# STM32F107 register map
File version: 1.1
CPU: CM3 r1p1, little endian, no MPU, no FPU, 4 interrupt priority bits
Registers are 32-bit, read-write, reset 0x0 unless marked. A register's access mark holds for its fields unless they carry their own. Offsets are from the block's base; [hi:lo] are bit positions.

## Ethernet_MMC — Ethernet: MAC management counters
Base 0x40028100
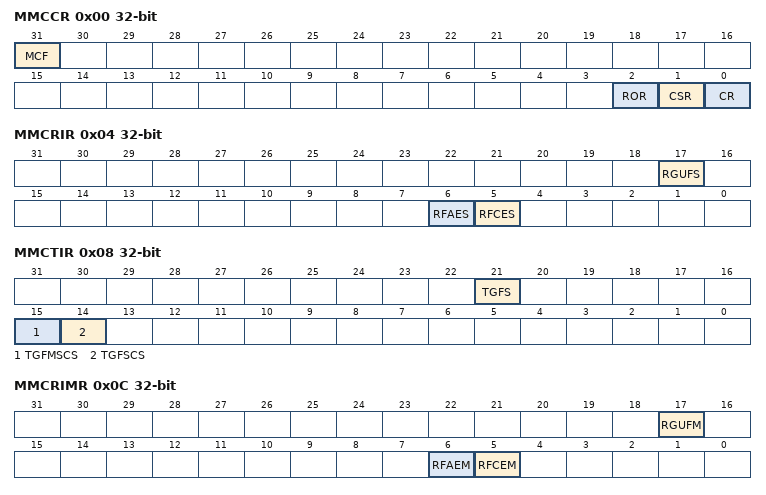
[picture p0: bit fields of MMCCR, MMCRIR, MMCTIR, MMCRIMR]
0x00 MMCCR — Ethernet MMC control register (ETH_MMCCR)
  [31] MCF — MMC counter freeze
    0=Unfrozen (All MMC counters update normally); 1=Frozen (All MMC counters frozen to their current value)
  [2] ROR — Reset on read
    0=Disabled (MMC counters do not reset on read); 1=Enabled (MMC counters reset to zero after read)
  [1] CSR — Counter stop rollover
    0=Disabled (Counters roll over to zero after reaching the maximum value); 1=Enabled (Counters do not roll over to zero after reaching the maximum value)
  [0] CR — Counter reset
    1=Reset all counters. Cleared automatically
0x04 MMCRIR — Ethernet MMC receive interrupt register (ETH_MMCRIR)
  [17] RGUFS — Received good Unicast frames status
  [6] RFAES — Received frames alignment error status
  [5] RFCES — Received frames CRC error status
0x08 MMCTIR — Ethernet MMC transmit interrupt register (ETH_MMCTIR)
  [21] TGFS — Transmitted good frames status
  [15] TGFMSCS — Transmitted good frames more than single collision status
  [14] TGFSCS — Transmitted good frames single collision status
0x0C MMCRIMR — Ethernet MMC receive interrupt mask register (ETH_MMCRIMR)
  [17] RGUFM — Received good Unicast frames mask
    0=Unmasked (Received-good-unicast counter half-full interrupt enabled); 1=Masked (Received-good-unicast counter half-full interrupt disabled)
  [6] RFAEM — Received frames alignment error mask
    0=Unmasked (Received-alignment-error counter half-full interrupt enabled); 1=Masked (Received-alignment-error counter half-full interrupt disabled)
  [5] RFCEM — Received frame CRC error mask
    0=Unmasked (Received-crc-error counter half-full interrupt enabled); 1=Masked (Received-crc-error counter half-full interrupt disabled)
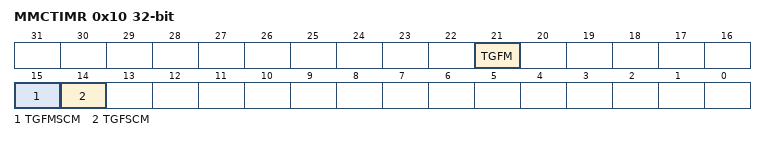
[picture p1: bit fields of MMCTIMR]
0x10 MMCTIMR — Ethernet MMC transmit interrupt mask register (ETH_MMCTIMR)
  [21] TGFM — Transmitted good frames mask
    0=Unmasked (Transmitted-good counter half-full interrupt enabled); 1=Masked (Transmitted-good counter half-full interrupt disabled)
  [15] TGFMSCM — Transmitted good frames more than single collision mask
    0=Unmasked (Transmitted-good-multiple-collision half-full interrupt enabled); 1=Masked (Transmitted-good-multiple-collision half-full interrupt disabled)
  [14] TGFSCM — Transmitted good frames single collision mask
    0=Unmasked (Transmitted-good-single-collision half-full interrupt enabled); 1=Masked (Transmitted-good-single-collision half-full interrupt disabled)
0x4C MMCTGFSCCR ro — Ethernet MMC transmitted good frames after a single collision counter
  [31:0] TGFSCC — Transmitted good frames single collision counter
0x50 MMCTGFMSCCR ro — Ethernet MMC transmitted good frames after more than a single collision
  [31:0] TGFMSCC — Transmitted good frames after more than a single collision counter
0x68 MMCTGFCR ro — Ethernet MMC transmitted good frames counter register
  [31:0] TGFC — Transmitted good frames counter
0x94 MMCRFCECR ro — Ethernet MMC received frames with CRC error counter register
  [31:0] RFCFC — Received frames with CRC error counter
0x98 MMCRFAECR ro — Ethernet MMC received frames with alignment error counter register
  [31:0] RFAEC — Received frames with alignment error counter
0xC4 MMCRGUFCR ro — MMC received good unicast frames counter register
  [31:0] RGUFC — Received good unicast frames counter

## Ethernet_PTP — Ethernet: Precision time protocol
Base 0x40028700
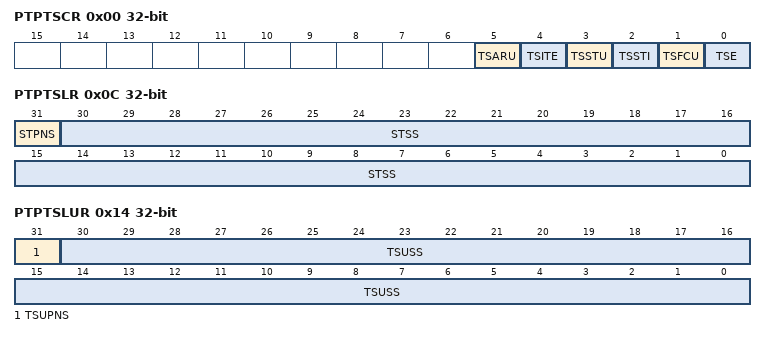
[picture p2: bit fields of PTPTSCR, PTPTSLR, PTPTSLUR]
0x00 PTPTSCR — Ethernet PTP time stamp control register (ETH_PTPTSCR)
  [5] TSARU — Time stamp addend register update
  [4] TSITE — Time stamp interrupt trigger enable
  [3] TSSTU — Time stamp system time update
  [2] TSSTI — Time stamp system time initialize
  [1] TSFCU — Time stamp fine or coarse update
  [0] TSE — Time stamp enable
0x04 PTPSSIR — Ethernet PTP subsecond increment register
  [7:0] STSSI — System time subsecond increment
0x08 PTPTSHR ro — Ethernet PTP time stamp high register
  [31:0] STS — System time second
0x0C PTPTSLR ro — Ethernet PTP time stamp low register (ETH_PTPTSLR)
  [31] STPNS — System time positive or negative sign
  [30:0] STSS — System time subseconds
0x10 PTPTSHUR — Ethernet PTP time stamp high update register
  [31:0] TSUS — Time stamp update second
0x14 PTPTSLUR — Ethernet PTP time stamp low update register (ETH_PTPTSLUR)
  [31] TSUPNS — Time stamp update positive or negative sign
  [30:0] TSUSS — Time stamp update subseconds
0x18 PTPTSAR — Ethernet PTP time stamp addend register
  [31:0] TSA — Time stamp addend
0x1C PTPTTHR — Ethernet PTP target time high register
  [31:0] TTSH — Target time stamp high
0x20 PTPTTLR — Ethernet PTP target time low register
  [31:0] TTSL — Target time stamp low
